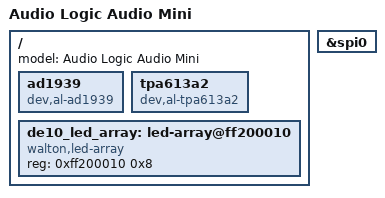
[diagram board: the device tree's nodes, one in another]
// SPDX-License-Identifier: GPL-2.0+

#include "socfpga_cyclone5_de10_nano.dtsi"

/ 
    {
    model = "Audio Logic Audio Mini";
    ad1939 {
        compatible = "dev,al-ad1939";
    };
    tpa613a2 {
        compatible = "dev,al-tpa613a2";
    };

    de10_led_array: led-array@ff200010 {
        compatible = "walton,led-array";
        reg = <0xff200010 0x8>;
    };

};

&spi0 {
    status = "okay";
};

